# SAM9X60D5M device description
Architecture: ARM926EJ-S; Family: SAM9; Series: SAM9X
Registers are 32-bit, read-write, no defined reset value unless marked. A register's access mark holds for its fields unless they carry their own. Offsets are from the block's base; [hi:lo] are bit positions.

## QSPI — Quad Serial Peripheral Interface
Instances: QSPI 0xF0014000
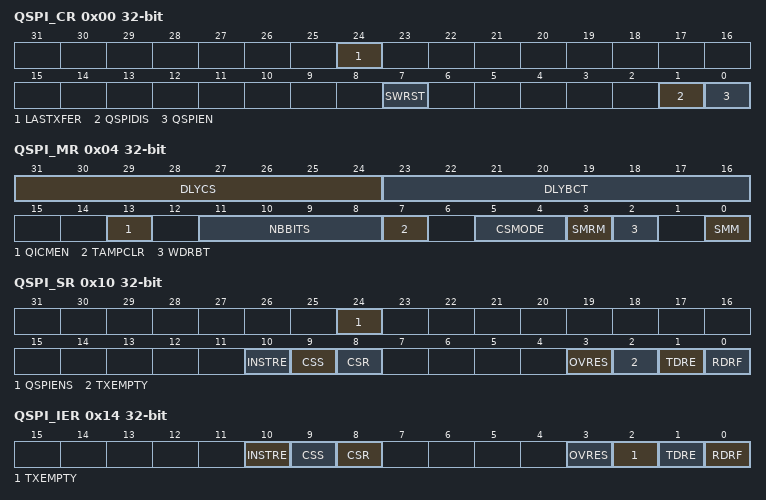
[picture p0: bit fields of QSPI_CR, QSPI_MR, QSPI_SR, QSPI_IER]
0x00 QSPI_CR wo — Control Register
  [24] LASTXFER — Last Transfer
  [7] SWRST — QSPI Software Reset
  [1] QSPIDIS — QSPI Disable
  [0] QSPIEN — QSPI Enable
0x04 QSPI_MR — Mode Register
  [31:24] DLYCS — Minimum Inactive QCS Delay
  [23:16] DLYBCT — Delay Between Consecutive Transfers
  [13] QICMEN — QSPI Inter-chip Mode Enable
    0=DISABLED (QSPI_WICR.WROPT and QSPI_RICR.RDOPT define the transfer options and QSPI_IFR.NBDUM defines the number of dummy cycles.); 1=ENABLED (No dummy cycles are inserted for write accesses, whatever the value configured in QSPI_IFR.NBDUM. The option field of the frame is automatically generated by QSPI depending on the type system bus transfer (the fields QSPI_RICR.RDOPT and QSPI_WICR.WROPT have no effect). Refer to section "Slave Quad SPI Interface (SQSPI)" for more details.)
  [11:8] NBBITS — Number Of Bits Per Transfer
    0=_8_BIT (8 bits for transfer); 8=_16_BIT (16 bits for transfer)
  [7] TAMPCLR — Tamper Clear Enable
  [5:4] CSMODE — Chip Select Mode
    0=NOT_RELOADED (The chip select is deasserted if QSPI_TDR.TD has not been reloaded before the end of the current transfer.); 1=LASTXFER (The chip select is deasserted when the bit LASTXFER is written to '1' and the character written in QSPI_TDR.TD has been transferred.); 2=SYSTEMATICALLY (The chip select is deasserted systematically after each transfer.)
  [3] SMRM — Serial Memory Register Mode
  [2] WDRBT — Wait Data Read Before Transfer
    0=DISABLED (No effect. In SPI mode, a transfer can be initiated whatever the state of the QSPI_RDR is.); 1=ENABLED (In SPI mode, a transfer can start only if the QSPI_RDR is empty, i.e., does not contain any unread data. This mode prevents overrun error in reception.)
  [0] SMM — Serial Memory Mode
    0=SPI (The QSPI is in SPI mode.); 1=MEMORY (The QSPI is in Serial Memory mode.)
0x08 QSPI_RDR ro — Receive Data Register
  [15:0] RD — Receive Data
0x0C QSPI_TDR wo — Transmit Data Register
  [15:0] TD — Transmit Data
0x10 QSPI_SR ro — Status Register
  [24] QSPIENS — QSPI Enable Status
  [10] INSTRE — Instruction End Status (cleared on read)
  [9] CSS — Chip Select Status
  [8] CSR — Chip Select Rise (cleared on read)
  [3] OVRES — Overrun Error Status (cleared on read)
  [2] TXEMPTY — Transmission Registers Empty (cleared by writing QSPI_TDR)
  [1] TDRE — Transmit Data Register Empty (cleared by writing QSPI_TDR)
  [0] RDRF — Receive Data Register Full (cleared by reading QSPI_RDR)
0x14 QSPI_IER wo — Interrupt Enable Register
  [10] INSTRE — Instruction End Interrupt Enable
  [9] CSS — Chip Select Status Interrupt Enable
  [8] CSR — Chip Select Rise Interrupt Enable
  [3] OVRES — Overrun Error Interrupt Enable
  [2] TXEMPTY — Transmission Registers Empty Enable
  [1] TDRE — Transmit Data Register Empty Interrupt Enable
  [0] RDRF — Receive Data Register Full Interrupt Enable
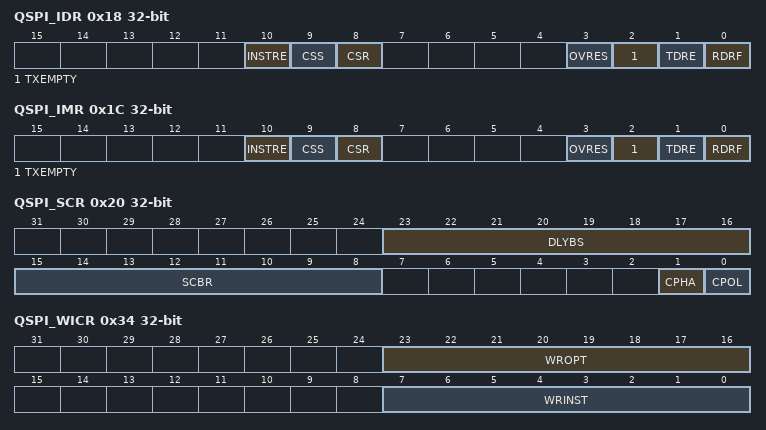
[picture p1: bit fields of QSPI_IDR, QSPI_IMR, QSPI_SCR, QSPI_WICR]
0x18 QSPI_IDR wo — Interrupt Disable Register
  [10] INSTRE — Instruction End Interrupt Disable
  [9] CSS — Chip Select Status Interrupt Disable
  [8] CSR — Chip Select Rise Interrupt Disable
  [3] OVRES — Overrun Error Interrupt Disable
  [2] TXEMPTY — Transmission Registers Empty Disable
  [1] TDRE — Transmit Data Register Empty Interrupt Disable
  [0] RDRF — Receive Data Register Full Interrupt Disable
0x1C QSPI_IMR ro — Interrupt Mask Register
  [10] INSTRE — Instruction End Interrupt Mask
  [9] CSS — Chip Select Status Interrupt Mask
  [8] CSR — Chip Select Rise Interrupt Mask
  [3] OVRES — Overrun Error Interrupt Mask
  [2] TXEMPTY — Transmission Registers Empty Mask
  [1] TDRE — Transmit Data Register Empty Interrupt Mask
  [0] RDRF — Receive Data Register Full Interrupt Mask
0x20 QSPI_SCR — Serial Clock Register
  [23:16] DLYBS — Delay Before QSCK
  [15:8] SCBR — Serial Clock Baud Rate
  [1] CPHA — Clock Phase
  [0] CPOL — Clock Polarity
0x30 QSPI_IAR — Instruction Address Register
  [31:0] ADDR — Address
0x34 QSPI_WICR — Write Instruction Code Register
  [23:16] WROPT — Write Option Code
  [7:0] WRINST — Write Instruction Code
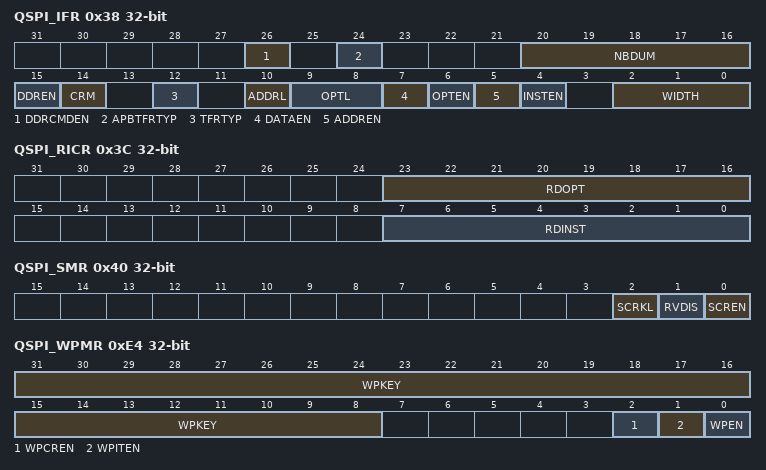
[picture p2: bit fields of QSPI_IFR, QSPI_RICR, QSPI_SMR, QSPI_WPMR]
0x38 QSPI_IFR — Instruction Frame Register
  [26] DDRCMDEN — DDR Mode Command Enable
    0=DISABLED (Transfer of instruction field is performed in Single Data Rate mode even if DDREN bit is written to '1'.); 1=ENABLED (Transfer of instruction field is performed in Double Data Rate mode if DDREN bit is written to '1'. If DDREN bit is written to '0', the instruction field is sent in Single Data Rate mode.)
  [24] APBTFRTYP — APB Transfer Type
  [20:16] NBDUM — Number Of Dummy Cycles
  [15] DDREN — DDR Mode Enable
    0=DISABLED (Transfers are performed in Single Data Rate mode.); 1=ENABLED (Transfers are performed in Double Data Rate mode, whereas the instruction field is still transferred in Single Data Rate mode.)
  [14] CRM — Continuous Read Mode
    0=DISABLED (Continuous Read mode is disabled.); 1=ENABLED (Continuous Read mode is enabled.)
  [12] TFRTYP — Data Transfer Type
    0=TRSFR_REGISTER (Read/Write transfer from the serial memory. Scrambling is not performed. Read at random location (fetch) in the serial Flash memory is not possible.); 1=TRSFR_MEMORY (Read/Write data transfer from the serial memory. If enabled, scrambling is performed. Read at random location (fetch) in the serial Flash memory is possible.)
  [10] ADDRL — Address Length
    0=_24_BIT (The address is 24 bits long.); 1=_32_BIT (The address is 32 bits long.)
  [9:8] OPTL — Option Code Length
    0=OPTION_1BIT (The option code is 1 bit long.); 1=OPTION_2BIT (The option code is 2 bits long.); 2=OPTION_4BIT (The option code is 4 bits long.); 3=OPTION_8BIT (The option code is 8 bits long.)
  [7] DATAEN — Data Enable
  [6] OPTEN — Option Enable
  [5] ADDREN — Address Enable
  [4] INSTEN — Instruction Enable
  [2:0] WIDTH — Width of Instruction Code, Address, Option Code and Data
    0=SINGLE_BIT_SPI (Instruction: Single-bit SPI / Address-Option: Single-bit SPI / Data: Single-bit SPI); 1=DUAL_OUTPUT (Instruction: Single-bit SPI / Address-Option: Single-bit SPI / Data: Dual SPI); 2=QUAD_OUTPUT (Instruction: Single-bit SPI / Address-Option: Single-bit SPI / Data: Quad SPI); 3=DUAL_IO (Instruction: Single-bit SPI / Address-Option: Dual SPI / Data: Dual SPI); 4=QUAD_IO (Instruction: Single-bit SPI / Address-Option: Quad SPI / Data: Quad SPI); 5=DUAL_CMD (Instruction: Dual SPI / Address-Option: Dual SPI / Data: Dual SPI); 6=QUAD_CMD (Instruction: Quad SPI / Address-Option: Quad SPI / Data: Quad SPI)
0x3C QSPI_RICR — Read Instruction Code Register
  [23:16] RDOPT — Read Option Code
  [7:0] RDINST — Read Instruction Code
0x40 QSPI_SMR — Scrambling Mode Register
  [2] SCRKL — Scrambling Key Lock
  [1] RVDIS — Scrambling/Unscrambling Random Value Disable
  [0] SCREN — Scrambling/Unscrambling Enable
    0=DISABLED (The scrambling/unscrambling is disabled.); 1=ENABLED (The scrambling/unscrambling is enabled.)
0x44 QSPI_SKR wo — Scrambling Key Register
  [31:0] USRK — User Scrambling Key
0xE4 QSPI_WPMR — Write Protection Mode Register
  [31:8] WPKEY — Write Protection Key
    0x515350=PASSWD (Writing any other value in this field aborts the write operation of the WPEN bit. Always reads as 0.)
  [2] WPCREN — Write Protection Control Register Enable
  [1] WPITEN — Write Protection Interrupt Enable
  [0] WPEN — Write Protection Enable
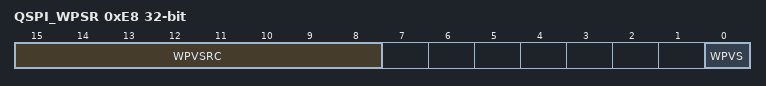
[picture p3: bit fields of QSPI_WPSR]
0xE8 QSPI_WPSR ro — Write Protection Status Register
  [15:8] WPVSRC — Write Protection Violation Source
  [0] WPVS — Write Protection Violation Status

## Notices in the file
Copyright (c) 2019 Microchip Technology Inc.
SPDX-License-Identifier: Apache-2.0
Licensed under the Apache License, Version 2.0 (the "License");
you may not use this file except in compliance with the License.
You may obtain a copy of the License at
http://www.apache.org/licenses/LICENSE-2.0
Unless required by applicable law or agreed to in writing, software
distributed under the License is distributed on an "AS IS" BASIS,
WITHOUT WARRANTIES OR CONDITIONS OF ANY KIND, either express or implied.
See the License for the specific language governing permissions and
limitations under the License.
